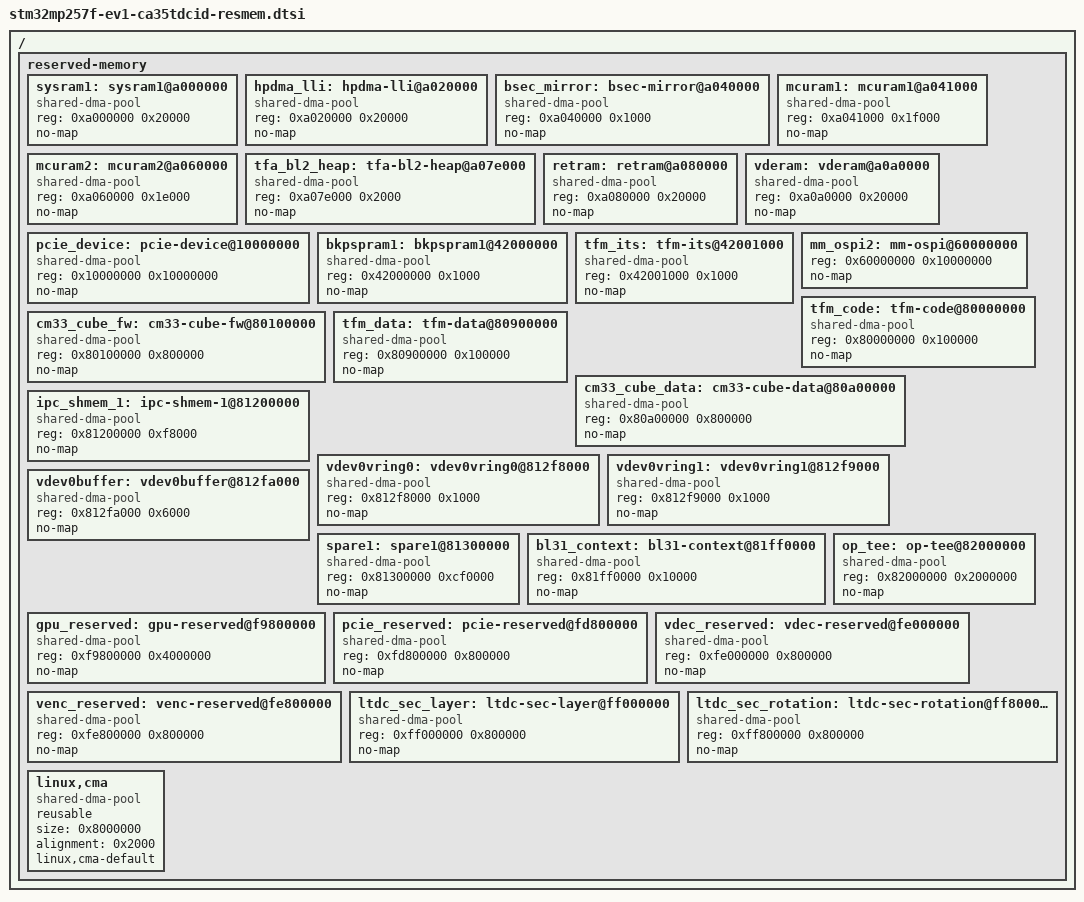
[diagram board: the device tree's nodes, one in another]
// SPDX-License-Identifier: (GPL-2.0-or-later OR BSD-3-Clause)
/*
 * Copyright (C) STMicroelectronics 2022 - All Rights Reserved
 * Author: Loic Pallardy loic.pallardy@foss.st.com for STMicroelectronics.
 */

/*
 * STM32MP25 reserved memory device tree configuration
 * Project : eco
 * Generated by XLmx tool version 2.2 - 4/18/2023 3:25:44 PM
 */

/ {
	reserved-memory {
		#address-cells = <1>;
		#size-cells = <1>;
		ranges;

		/* Internal RAM reserved memory declaration */
		sysram1: sysram1@a000000 {
			compatible = "shared-dma-pool";
			reg = <0xa000000 0x20000>;
			no-map;
		};

		hpdma_lli: hpdma-lli@a020000 {
			compatible = "shared-dma-pool";
			reg = <0xa020000 0x20000>;
			no-map;
		};

		bsec_mirror: bsec-mirror@a040000 {
			compatible = "shared-dma-pool";
			reg = <0xa040000 0x1000>;
			no-map;
		};

		mcuram1: mcuram1@a041000 {
			compatible = "shared-dma-pool";
			reg = <0xa041000 0x1f000>;
			no-map;
		};

		mcuram2: mcuram2@a060000 {
			compatible = "shared-dma-pool";
			reg = <0xa060000 0x1e000>;
			no-map;
		};

		tfa_bl2_heap: tfa-bl2-heap@a07e000 {
			compatible = "shared-dma-pool";
			reg = <0xa07e000 0x2000>;
			no-map;
		};

		retram: retram@a080000 {
			compatible = "shared-dma-pool";
			reg = <0xa080000 0x20000>;
			no-map;
		};

		vderam: vderam@a0a0000 {
			compatible = "shared-dma-pool";
			reg = <0xa0a0000 0x20000>;
			no-map;
		};

		/* PCIe reserved memory declaration */
		pcie_device: pcie-device@10000000 {
			compatible = "shared-dma-pool";
			reg = <0x10000000 0x10000000>;
			no-map;
		};

		/* Backup RAM reserved memory declaration */
		bkpspram1: bkpspram1@42000000 {
			compatible = "shared-dma-pool";
			reg = <0x42000000 0x1000>;
			no-map;
		};

		tfm_its: tfm-its@42001000 {
			compatible = "shared-dma-pool";
			reg = <0x42001000 0x1000>;
			no-map;
		};

		/* Octo Memory Manager reserved memory declaration */
		mm_ospi2: mm-ospi@60000000 {
			reg = <0x60000000 0x10000000>;
			no-map;
		};

		/* DDR reserved memory declaration */
		tfm_code: tfm-code@80000000 {
			compatible = "shared-dma-pool";
			reg = <0x80000000 0x100000>;
			no-map;
		};

		cm33_cube_fw: cm33-cube-fw@80100000 {
			compatible = "shared-dma-pool";
			reg = <0x80100000 0x800000>;
			no-map;
		};

		tfm_data: tfm-data@80900000 {
			compatible = "shared-dma-pool";
			reg = <0x80900000 0x100000>;
			no-map;
		};

		cm33_cube_data: cm33-cube-data@80a00000 {
			compatible = "shared-dma-pool";
			reg = <0x80a00000 0x800000>;
			no-map;
		};

		ipc_shmem_1: ipc-shmem-1@81200000 {
			compatible = "shared-dma-pool";
			reg = <0x81200000 0xf8000>;
			no-map;
		};

		vdev0vring0: vdev0vring0@812f8000 {
			compatible = "shared-dma-pool";
			reg = <0x812f8000 0x1000>;
			no-map;
		};

		vdev0vring1: vdev0vring1@812f9000 {
			compatible = "shared-dma-pool";
			reg = <0x812f9000 0x1000>;
			no-map;
		};

		vdev0buffer: vdev0buffer@812fa000 {
			compatible = "shared-dma-pool";
			reg = <0x812fa000 0x6000>;
			no-map;
		};

		spare1: spare1@81300000 {
			compatible = "shared-dma-pool";
			reg = <0x81300000 0xcf0000>;
			no-map;
		};

		bl31_context: bl31-context@81ff0000 {
			compatible = "shared-dma-pool";
			reg = <0x81ff0000 0x10000>;
			no-map;
		};

		op_tee: op-tee@82000000 {
			compatible = "shared-dma-pool";
			reg = <0x82000000 0x2000000>;
			no-map;
		};

		gpu_reserved: gpu-reserved@f9800000 {
			compatible = "shared-dma-pool";
			reg = <0xf9800000 0x4000000>;
			no-map;
		};

		pcie_reserved: pcie-reserved@fd800000 {
			compatible = "shared-dma-pool";
			reg = <0xfd800000 0x800000>;
			no-map;
		};

		vdec_reserved: vdec-reserved@fe000000 {
			compatible = "shared-dma-pool";
			reg = <0xfe000000 0x800000>;
			no-map;
		};

		venc_reserved: venc-reserved@fe800000 {
			compatible = "shared-dma-pool";
			reg = <0xfe800000 0x800000>;
			no-map;
		};

		ltdc_sec_layer: ltdc-sec-layer@ff000000 {
			compatible = "shared-dma-pool";
			reg = <0xff000000 0x800000>;
			no-map;
		};

		ltdc_sec_rotation: ltdc-sec-rotation@ff800000 {
			compatible = "shared-dma-pool";
			reg = <0xff800000 0x800000>;
			no-map;
		};

		/* global autoconfigured region for contiguous allocations */
		linux,cma {
			compatible = "shared-dma-pool";
			reusable;
			size = <0x8000000>;
			alignment = <0x2000>;
			linux,cma-default;
		};
	};
};
